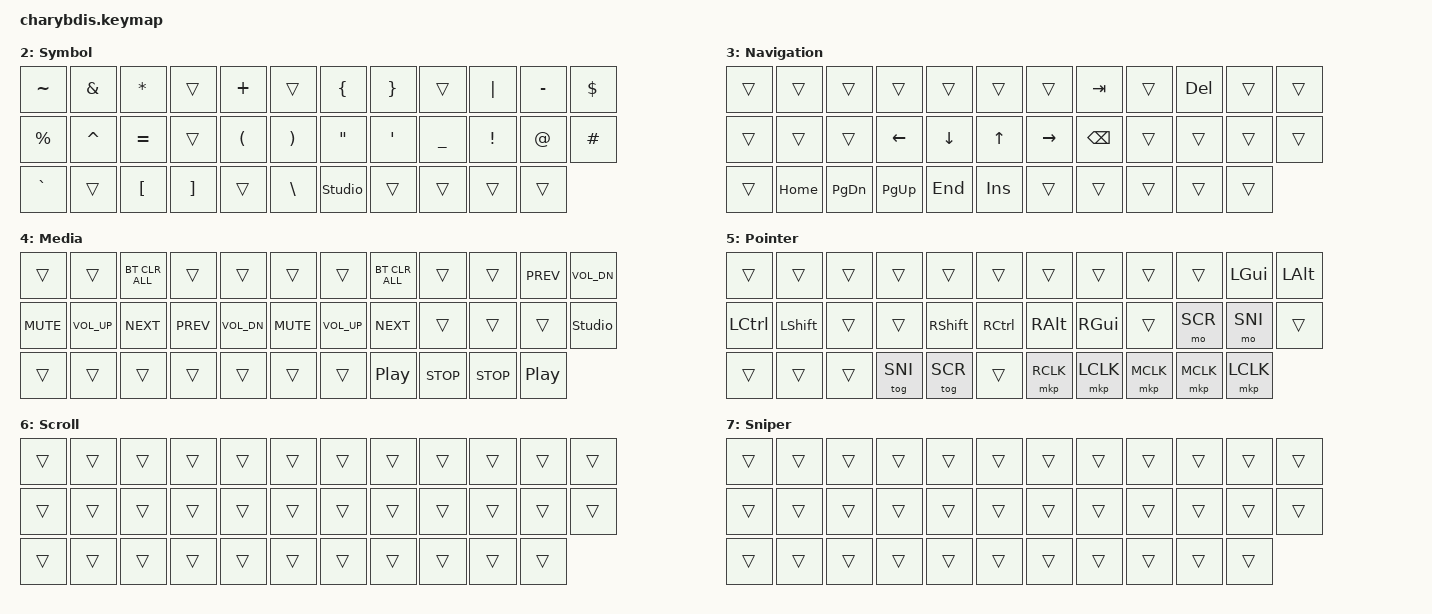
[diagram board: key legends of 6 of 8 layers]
#include <behaviors/mouse_keys.dtsi>
#include <dt-bindings/zmk/mouse.h>
#include <behaviors.dtsi>
#include <dt-bindings/zmk/bt.h>
#include <dt-bindings/zmk/ext_power.h>
#include <dt-bindings/zmk/keys.h>
#include <dt-bindings/zmk/pointing.h>
#include <dt-bindings/zmk/rgb.h>

#define BASE 0
#define NUFU 1
#define SYM 2
#define NAV 3
#define MED 4
#define POI 5
#define SCR 6
#define SNI 7

&sl { release-after-ms = <250>; };

&mt {
    tapping-term-ms = <200>;
    require-prior-idle-ms = <150>;
};

/ {
    #include "combos.dtsi"

    behaviors {
        hml: homewrow_mods_left {
            compatible = "zmk,behavior-hold-tap";
            label = "HOMEROW_MODS_LEFT_HAND";
            bindings = <&kp>, <&kp>;

            #binding-cells = <2>;
            tapping-term-ms = <280>;
            hold-trigger-key-positions = <5 6 7 8 9 15 16 17 18 19 25 26 27 28 29 33 34>;
            flavor = "balanced";
            quick-tap-ms = <175>;
            require-prior-idle-ms = <125>;
            hold-trigger-on-release;
        };

        hmr: homewrow_mods_right {
            compatible = "zmk,behavior-hold-tap";
            label = "HOMEROW_MODS_RIGHT_HAND";
            bindings = <&kp>, <&kp>;

            #binding-cells = <2>;
            tapping-term-ms = <280>;
            hold-trigger-key-positions = <0 1 2 3 4 10 11 12 13 14 20 21 22 23 24 30 31 32>;
            flavor = "balanced";
            quick-tap-ms = <175>;
            require-prior-idle-ms = <125>;
            hold-trigger-on-release;
        };
    };

    keymap {
        compatible = "zmk,keymap";

        Base {
            label = "Base";
            bindings = <
&kp ESC         &kp N1   &kp N2  &kp N3          &kp N4        &kp N5            &kp N6          &kp N7           &kp N8     &kp N9   &kp N0       &kp BSPC
&kp TAB         &kp Q    &kp W   &kp E           &kp R         &kp T             &kp Y           &kp U            &kp I      &kp O    &kp P        &kp BACKSLASH
&kp LEFT_SHIFT  &kp A    &kp S   &kp D           &kp F         &kp G             &kp H           &kp J            &kp K      &kp L    &kp SEMI     &kp APOS
&kp LCTRL       &lt 3 Z  &kp X   &kp C           &kp V         &kp B             &kp N           &kp M            &kp COMMA  &kp DOT  &lt 3 SLASH  &kp DELETE
                                 &kp LEFT_ARROW  &kp UP_ARROW  &lt 1 LEFT_WIN    &lt 2 ENTER     &kp RIGHT_ARROW
                                                 &kp LEFT_ALT  &kp SPACE         &kp DOWN_ARROW
            >;
        };

        NuFu {
            label = "Numeral/Function";
            bindings = <
&kp TILDE         &kp EXCLAMATION  &kp HASH      &kp DOLLAR    &kp DOLLAR       &kp PERCENT          &kp CARET        &kp AMPERSAND  &kp ASTERISK  &kp LEFT_PARENTHESIS  &kp RIGHT_PARENTHESIS  &kp UNDERSCORE
&kp GRAVE         &kp NUMBER_1     &kp NUMBER_2  &kp NUMBER_3  &kp NUMBER_4     &kp LBKT             &kp RBKT         &kp F1         &kp F2        &kp F3                &kp F4                 &kp DEL
&kp LEFT_CONTROL  &kp NUMBER_5     &kp NUMBER_6  &kp NUMBER_7  &kp NUMBER_8     &soft_off            &kp BSLH         &kp F5         &kp F6        &kp F7                &kp F8                 &kp PAGE_UP
&kp LSHFT         &kp NUMBER_9     &kp NUMBER_0  &kp MINUS     &kp EQUAL        &ext_power EP_TOG    &rgb_ug RGB_TOG  &kp F9         &kp F10       &kp F11               &kp F12                &kp PAGE_DOWN
                                                 &kp LEFT_WIN  &kp SPACE        &none                &kp ENTER        &kp BACKSPACE
                                                               &rgb_ug RGB_BRI  &rgb_ug RGB_BRD      &rgb_ug RGB_EFF
            >;
        };

        Symbol {
            label = "Symbol";
            bindings = <
&kp TILDE  &kp AMPS   &kp STAR   &trans    &kp PLUS  &trans      &kp LBRC        &kp RBRC  &trans     &kp PIPE  &kp MINUS  &kp DLLR
&kp PRCNT  &kp CARET  &kp EQUAL  &trans    &kp LPAR  &kp RPAR    &kp DQT         &kp APOS  &kp UNDER  &kp EXCL  &kp AT     &kp HASH
&kp GRAVE  &trans     &kp LBKT   &kp RBKT  &trans    &kp BSLH    &studio_unlock  &trans    &trans     &trans    &trans
            >;
        };

        Navigation {
            label = "Navigation";
            bindings = <
&trans  &trans    &trans         &trans       &trans    &trans     &trans     &kp TAB        &trans  &kp DELETE  &trans  &trans
&trans  &trans    &trans         &kp LEFT     &kp DOWN  &kp UP     &kp RIGHT  &kp BACKSPACE  &trans  &trans      &trans  &trans
&trans  &kp HOME  &kp PAGE_DOWN  &kp PAGE_UP  &kp END   &kp INS    &trans     &trans         &trans  &trans      &trans
            >;
        };

        Media {
            label = "Media";
            bindings = <
&trans      &trans        &bt BT_CLR_ALL  &trans      &trans        &trans        &trans        &bt BT_CLR_ALL    &trans      &trans      &kp C_PREV        &kp C_VOL_DN
&kp C_MUTE  &kp C_VOL_UP  &kp C_NEXT      &kp C_PREV  &kp C_VOL_DN  &kp C_MUTE    &kp C_VOL_UP  &kp C_NEXT        &trans      &trans      &trans            &studio_unlock
&trans      &trans        &trans          &trans      &trans        &trans        &trans        &kp C_PLAY_PAUSE  &kp C_STOP  &kp C_STOP  &kp C_PLAY_PAUSE
            >;
        };

        Pointer {
            label = "Pointer";
            bindings = <
&trans     &trans     &trans  &trans    &trans     &trans       &trans     &trans     &trans     &trans     &kp LGUI   &kp LALT
&kp LCTRL  &kp LSHFT  &trans  &trans    &kp RSHFT  &kp RCTRL    &kp RALT   &kp RGUI   &trans     &mo SCR    &mo SNI    &trans
&trans     &trans     &trans  &tog SNI  &tog SCR   &trans       &mkp RCLK  &mkp LCLK  &mkp MCLK  &mkp MCLK  &mkp LCLK
            >;
        };

        Scroll {
            label = "Scroll";
            bindings = <
&trans  &trans  &trans  &trans  &trans  &trans    &trans  &trans  &trans  &trans  &trans  &trans
&trans  &trans  &trans  &trans  &trans  &trans    &trans  &trans  &trans  &trans  &trans  &trans
&trans  &trans  &trans  &trans  &trans  &trans    &trans  &trans  &trans  &trans  &trans
            >;
        };

        Sniper {
            label = "Sniper";
            bindings = <
&trans  &trans  &trans  &trans  &trans  &trans    &trans  &trans  &trans  &trans  &trans  &trans
&trans  &trans  &trans  &trans  &trans  &trans    &trans  &trans  &trans  &trans  &trans  &trans
&trans  &trans  &trans  &trans  &trans  &trans    &trans  &trans  &trans  &trans  &trans
            >;
        };
    };
};
